# STM32U595 register map
File version: 0.2
CPU: CM33 r0p1, little endian, MPU, FPU, 4 interrupt priority bits
Registers are 32-bit, read-write, reset 0x0 unless marked. A register's access mark holds for its fields unless they carry their own. Offsets are from the block's base; [hi:lo] are bit positions; {n}, {i} and the like mark numbered series.

## SPI1 — Serial peripheral interface
Base 0x40013000
Same registers: SPI2 0x40003800, SPI3 0x46002000, SEC_SPI2 0x50003800, SEC_SPI1 0x50013000, SEC_SPI3 0x56002000
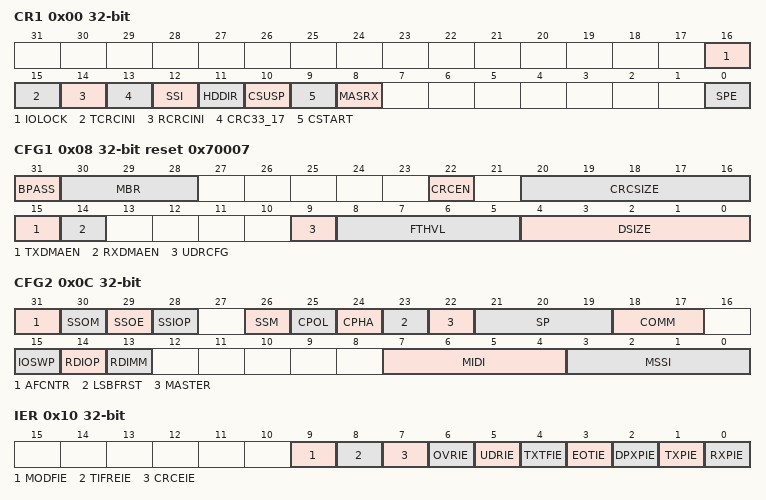
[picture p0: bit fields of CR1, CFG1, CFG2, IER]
0x00 CR1 access per field — control register 1
  [16] IOLOCK rw, [15] TCRCINI rw, [14] RCRCINI rw, [13] CRC33_17 rw, [12] SSI rw, [11] HDDIR rw, [10] CSUSP wo, [9] CSTART rw, [8] MASRX rw, [0] SPE rw
0x04 CR2 — control register 2
  [15:0] TSIZE
0x08 CFG1 reset 0x70007 — configuration register 1
  [31] BPASS
  [30:28] MBR — Master baud rate
  [22] CRCEN — Hardware CRC computation enable
  [20:16] CRCSIZE — Length of CRC frame to be transacted and compared
  [15] TXDMAEN — Tx DMA stream enable
  [14] RXDMAEN — Rx DMA stream enable
  [9] UDRCFG — Behavior of slave transmitter at underrun condition
  [8:5] FTHVL — threshold level
  [4:0] DSIZE — Number of bits in at single SPI data frame
0x0C CFG2 — configuration register 2
  [31] AFCNTR — Alternate function GPIOs control
  [30] SSOM — SS output management in master mode
  [29] SSOE — SS output enable
  [28] SSIOP — SS input/output polarity
  [26] SSM — Software management of SS signal input
  [25] CPOL — Clock polarity
  [24] CPHA — Clock phase
  [23] LSBFRST — Data frame format
  [22] MASTER — SPI Master
  [21:19] SP — Serial Protocol
  [18:17] COMM — SPI Communication Mode
  [15] IOSWP — Swap functionality of MISO and MOSI pins
  [14] RDIOP
  [13] RDIMM
  [7:4] MIDI — Master Inter-Data Idleness
  [3:0] MSSI — Master SS Idleness
0x10 IER — Interrupt Enable Register
  [9] MODFIE — Mode Fault interrupt enable
  [8] TIFREIE — TIFRE interrupt enable
  [7] CRCEIE — CRC Interrupt enable
  [6] OVRIE — OVR interrupt enable
  [5] UDRIE — UDR interrupt enable
  [4] TXTFIE — TXTFIE interrupt enable
  [3] EOTIE — EOT, SUSP and TXC interrupt enable
  [2] DPXPIE — DXP interrupt enabled
  [1] TXPIE — TXP interrupt enable
  [0] RXPIE — RXP Interrupt Enable
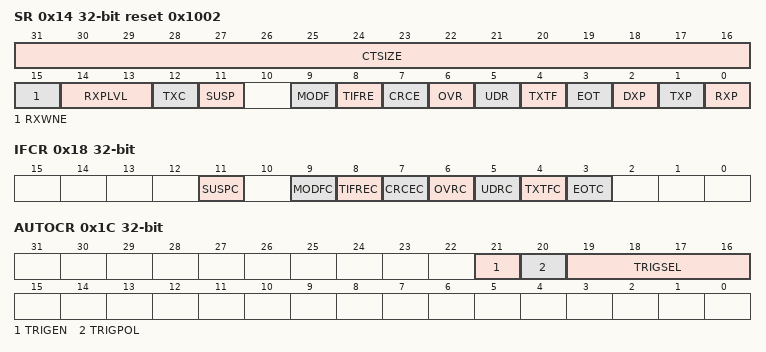
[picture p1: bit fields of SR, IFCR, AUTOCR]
0x14 SR ro reset 0x1002 — Status Register
  [31:16] CTSIZE — Number of data frames remaining in current TSIZE session
  [15] RXWNE — RxFIFO Word Not Empty
  [14:13] RXPLVL — RxFIFO Packing LeVeL
  [12] TXC — TxFIFO transmission complete
  [11] SUSP — SUSPend
  [9] MODF — Mode Fault
  [8] TIFRE — TI frame format error
  [7] CRCE — CRC Error
  [6] OVR — Overrun
  [5] UDR — Underrun at slave transmission mode
  [4] TXTF — Transmission Transfer Filled
  [3] EOT — End Of Transfer
  [2] DXP — Duplex Packet
  [1] TXP — Tx-Packet space available
  [0] RXP — Rx-Packet available
0x18 IFCR wo — Interrupt/Status Flags Clear Register
  [11] SUSPC — SUSPend flag clear
  [9] MODFC — Mode Fault flag clear
  [8] TIFREC — TI frame format error flag clear
  [7] CRCEC — CRC Error flag clear
  [6] OVRC — Overrun flag clear
  [5] UDRC — Underrun flag clear
  [4] TXTFC — Transmission Transfer Filled flag clear
  [3] EOTC — End Of Transfer flag clear
0x1C AUTOCR — SPI autonomous mode control register
  [21] TRIGEN, [20] TRIGPOL, [19:16] TRIGSEL
0x20 TXDR wo — Transmit Data Register
  [31:0] TXDR — Transmit data register
0x30 RXDR ro — Receive Data Register
  [31:0] RXDR — Receive data register
0x40 CRCPOLY reset 0x107 — Polynomial Register
  [31:0] CRCPOLY — CRC polynomial register
0x44 TXCRC ro — Transmitter CRC Register
  [31:0] TXCRC — CRC register for transmitter
0x48 RXCRC ro — Receiver CRC Register
  [31:0] RXCRC — CRC register for receiver
0x4C UDRDR — Underrun Data Register
  [31:0] UDRDR — Data at slave underrun condition

## SYSCFG — System configuration controller
Base 0x46000400
Same registers: SEC_SYSCFG 0x56000400
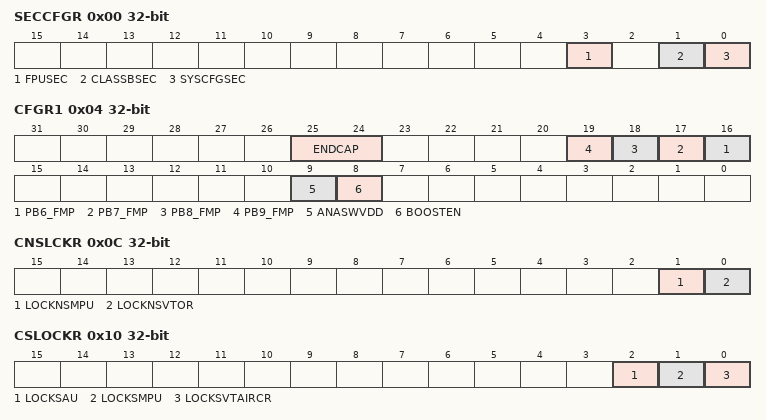
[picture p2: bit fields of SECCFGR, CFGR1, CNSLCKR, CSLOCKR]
0x00 SECCFGR — SYSCFG secure configuration register
  [3] FPUSEC
  [1] CLASSBSEC
  [0] SYSCFGSEC — SYSCFG clock control security
0x04 CFGR1 — configuration register 1
  [25:24] ENDCAP
  [n+10] PB{n}_FMP (n=6..9)
  [9] ANASWVDD — GPIO analog switch control voltage selection
  [8] BOOSTEN — I/O analog switch voltage booster enable
0x08 FPUIMR reset 0x1F — FPU interrupt mask register
  [5:0] FPU_IE — Floating point unit interrupts enable bits
0x0C CNSLCKR — SYSCFG CPU non-secure lock register
  [1] LOCKNSMPU — Non-secure MPU registers lock
  [0] LOCKNSVTOR — VTOR_NS register lock
0x10 CSLOCKR — SYSCFG CPU secure lock register
  [2] LOCKSAU, [1] LOCKSMPU, [0] LOCKSVTAIRCR
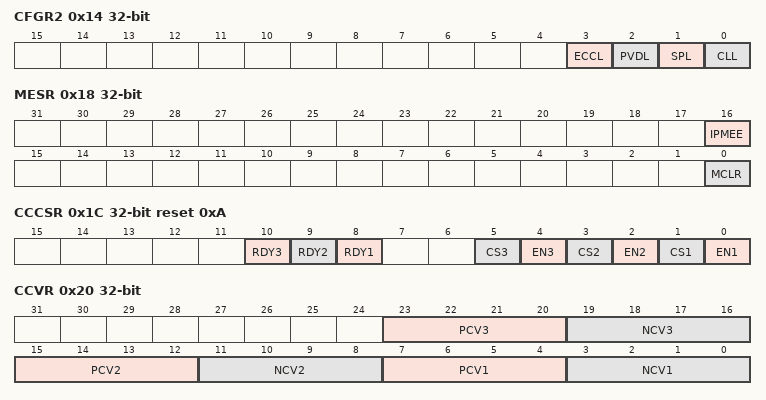
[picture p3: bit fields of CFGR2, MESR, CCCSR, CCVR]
0x14 CFGR2 — configuration register 2
  [3] ECCL — ECC Lock
  [2] PVDL — PVD lock enable bit
  [1] SPL — SRAM ECC lock bit
  [0] CLL — LOCKUP (hardfault) output enable bit
0x18 MESR — memory erase status register
  [16] IPMEE, [0] MCLR
0x1C CCCSR access per field reset 0xA — compensation cell control/status register
  [10] RDY3 ro, [9] RDY2 ro, [8] RDY1 ro, [5] CS3 rw, [4] EN3 rw, [3] CS2 rw, [2] EN2 rw, [1] CS1 rw, [0] EN1 rw
0x20 CCVR ro — compensation cell value register
  [23:20] PCV3, [19:16] NCV3, [15:12] PCV2, [11:8] NCV2, [7:4] PCV1, [3:0] NCV1
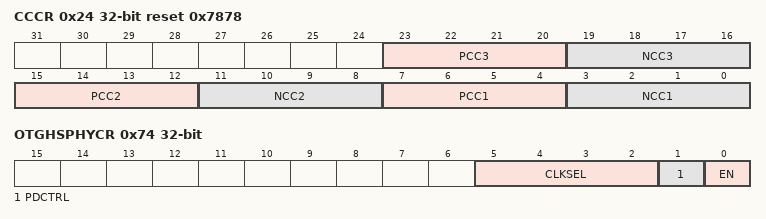
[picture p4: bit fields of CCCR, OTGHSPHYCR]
0x24 CCCR reset 0x7878 — compensation cell code register
  [23:20] PCC3, [19:16] NCC3, [15:12] PCC2, [11:8] NCC2, [7:4] PCC1, [3:0] NCC1
0x2C RSSCMDR — RSS command register
  [15:0] RSSCMD — RSS commands
0x74 OTGHSPHYCR — SYSCFG USB OTG_HS PHY register
  [5:2] CLKSEL, [1] PDCTRL, [0] EN
